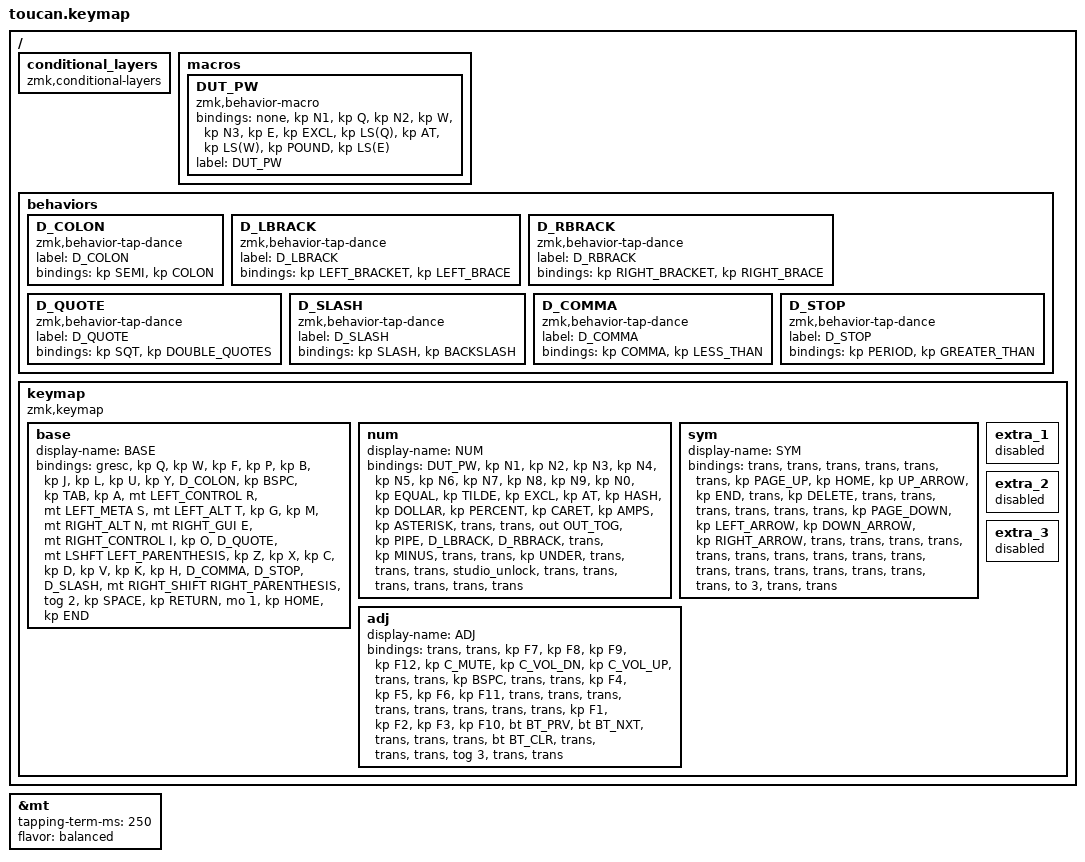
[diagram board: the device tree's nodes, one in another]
#include <behaviors.dtsi>
#include <dt-bindings/zmk/bt.h>
#include <dt-bindings/zmk/keys.h>
#include <dt-bindings/zmk/outputs.h>

#define BASE 0
#define NAV  1
#define SYM  2
#define ADJ  3

&mt {
    tapping-term-ms = <250>;
    flavor = "balanced";
};

/ {
    conditional_layers { compatible = "zmk,conditional-layers"; };

    macros {
        DUT_PW: DUT_PW {
            compatible = "zmk,behavior-macro";
            #binding-cells = <0>;
            bindings = <&none &kp N1 &kp Q &kp N2 &kp W &kp N3 &kp E &kp EXCL &kp LS(Q) &kp AT &kp LS(W) &kp POUND &kp LS(E)>;
            label = "DUT_PW";
        };
    };

    behaviors {
        D_COLON: D_COLON {
            compatible = "zmk,behavior-tap-dance";
            label = "D_COLON";
            #binding-cells = <0>;
            bindings = <&kp SEMI>, <&kp COLON>;
        };

        D_LBRACK: D_LBRACK {
            compatible = "zmk,behavior-tap-dance";
            label = "D_LBRACK";
            #binding-cells = <0>;
            bindings = <&kp LEFT_BRACKET>, <&kp LEFT_BRACE>;
        };

        D_RBRACK: D_RBRACK {
            compatible = "zmk,behavior-tap-dance";
            label = "D_RBRACK";
            #binding-cells = <0>;
            bindings = <&kp RIGHT_BRACKET>, <&kp RIGHT_BRACE>;
        };

        D_QUOTE: D_QUOTE {
            compatible = "zmk,behavior-tap-dance";
            label = "D_QUOTE";
            #binding-cells = <0>;
            bindings = <&kp SQT>, <&kp DOUBLE_QUOTES>;
        };

        D_SLASH: D_SLASH {
            compatible = "zmk,behavior-tap-dance";
            label = "D_SLASH";
            #binding-cells = <0>;
            bindings = <&kp SLASH>, <&kp BACKSLASH>;
        };

        D_COMMA: D_COMMA {
            compatible = "zmk,behavior-tap-dance";
            label = "D_COMMA";
            #binding-cells = <0>;
            bindings = <&kp COMMA>, <&kp LESS_THAN>;
        };

        D_STOP: D_STOP {
            compatible = "zmk,behavior-tap-dance";
            label = "D_STOP";
            #binding-cells = <0>;
            bindings = <&kp PERIOD>, <&kp GREATER_THAN>;
        };
    };

    keymap {
        compatible = "zmk,keymap";

        base {
            display-name = "BASE";
            bindings = <
&gresc  &kp Q  &kp W  &kp F  &kp P  &kp B  &kp J  &kp L  &kp U  &kp Y  &D_COLON  &kp BSPC  &kp TAB  &kp A  &mt LEFT_CONTROL R  &mt LEFT_META S  &mt LEFT_ALT T  &kp G  &kp M  &mt RIGHT_ALT N  &mt RIGHT_GUI E  &mt RIGHT_CONTROL I  &kp O  &D_QUOTE  &mt LSHFT LEFT_PARENTHESIS  &kp Z  &kp X  &kp C  &kp D  &kp V  &kp K  &kp H  &D_COMMA  &D_STOP  &D_SLASH  &mt RIGHT_SHIFT RIGHT_PARENTHESIS  &tog 2  &kp SPACE  &kp RETURN  &mo 1  &kp HOME  &kp END
            >;
        };

        num {
            display-name = "NUM";
            bindings = <
&DUT_PW  &kp N1  &kp N2  &kp N3  &kp N4  &kp N5  &kp N6  &kp N7  &kp N8  &kp N9  &kp N0  &kp EQUAL  &kp TILDE  &kp EXCL  &kp AT  &kp HASH  &kp DOLLAR  &kp PERCENT  &kp CARET  &kp AMPS  &kp ASTERISK  &trans  &trans  &out OUT_TOG  &kp PIPE  &D_LBRACK  &D_RBRACK  &trans  &kp MINUS  &trans  &trans  &kp UNDER  &trans  &trans  &trans  &studio_unlock  &trans  &trans  &trans  &trans  &trans  &trans
            >;
        };

        sym {
            display-name = "SYM";
            bindings = <
&trans  &trans  &trans  &trans  &trans  &trans  &kp PAGE_UP  &kp HOME  &kp UP_ARROW  &kp END  &trans  &kp DELETE  &trans  &trans  &trans  &trans  &trans  &trans  &kp PAGE_DOWN  &kp LEFT_ARROW  &kp DOWN_ARROW  &kp RIGHT_ARROW  &trans  &trans  &trans  &trans  &trans  &trans  &trans  &trans  &trans  &trans  &trans  &trans  &trans  &trans  &trans  &trans  &trans  &to 3  &trans  &trans
            >;
        };

        adj {
            display-name = "ADJ";
            bindings = <
&trans  &trans  &kp F7  &kp F8  &kp F9  &kp F12  &kp C_MUTE  &kp C_VOL_DN  &kp C_VOL_UP  &trans  &trans  &kp BSPC  &trans  &trans  &kp F4  &kp F5  &kp F6  &kp F11  &trans  &trans  &trans  &trans  &trans  &trans  &trans  &trans  &kp F1  &kp F2  &kp F3  &kp F10  &bt BT_PRV  &bt BT_NXT  &trans  &trans  &trans  &bt BT_CLR  &trans  &trans  &trans  &tog 3  &trans  &trans
            >;
        };

        extra_1 { status = "reserved"; };

        extra_2 { status = "reserved"; };

        extra_3 { status = "reserved"; };
    };
};
